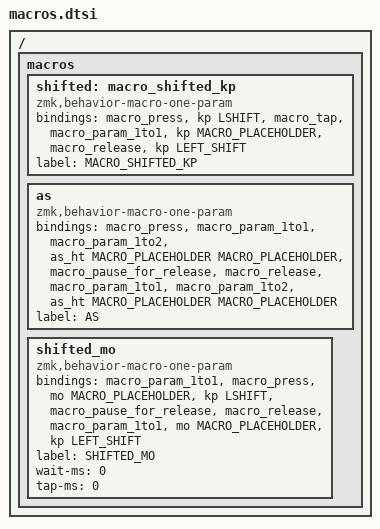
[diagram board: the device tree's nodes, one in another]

/ {
    macros {
        shifted: macro_shifted_kp {
            compatible = "zmk,behavior-macro-one-param";
            #binding-cells = <1>;
            bindings =
                <&macro_press>,
                <&kp LSHIFT>,
                <&macro_tap>,
                <&macro_param_1to1 &kp MACRO_PLACEHOLDER>,
                <&macro_release>,
                <&kp LEFT_SHIFT>;

            label = "MACRO_SHIFTED_KP";
        };

        as: as {
            compatible = "zmk,behavior-macro-one-param";
            #binding-cells = <1>;
            bindings =
                <&macro_press>,
                <&macro_param_1to1 &macro_param_1to2 &as_ht MACRO_PLACEHOLDER MACRO_PLACEHOLDER>,
                <&macro_pause_for_release>,
                <&macro_release>,
                <&macro_param_1to1 &macro_param_1to2 &as_ht MACRO_PLACEHOLDER MACRO_PLACEHOLDER>;

            label = "AS";
        };

        shifted_mo: shifted_mo {
            compatible = "zmk,behavior-macro-one-param";
            #binding-cells = <1>;
            bindings =
                <&macro_param_1to1>,
                <&macro_press>,
                <&mo MACRO_PLACEHOLDER &kp LSHIFT>,
                <&macro_pause_for_release>,
                <&macro_release>,
                <&macro_param_1to1 &mo MACRO_PLACEHOLDER &kp LEFT_SHIFT>;

            label = "SHIFTED_MO";
            wait-ms = <0>;
            tap-ms = <0>;
        };
    };
};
